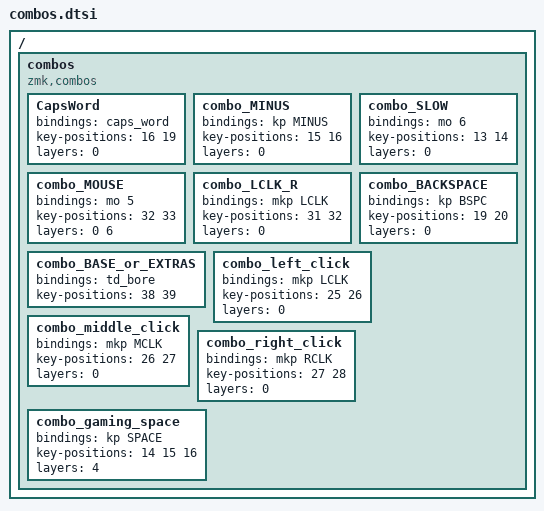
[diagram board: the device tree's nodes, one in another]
/ {
    combos {
        compatible = "zmk,combos";

        CapsWord {
            bindings = <&caps_word>;
            key-positions = <16 19>;
            layers = <0>;
        };

        combo_MINUS {
            bindings = <&kp MINUS>;
            key-positions = <15 16>;
            layers = <0>;
        };

        combo_SLOW {
            bindings = <&mo 6>;
            key-positions = <13 14>;
            layers = <0>;
        };

        combo_MOUSE {
            bindings = <&mo 5>;
            key-positions = <32 33>;
            layers = <0 6>;
        };

        combo_LCLK_R {
            bindings = <&mkp LCLK>;
            key-positions = <31 32>;
            layers = <0>;
        };

        combo_BACKSPACE {
            bindings = <&kp BSPC>;
            key-positions = <19 20>;
            layers = <0>;
        };

        combo_BASE_or_EXTRAS {
            bindings = <&td_bore>;
            key-positions = <38 39>;
        };

        combo_left_click {
            bindings = <&mkp LCLK>;
            key-positions = <25 26>;
            layers = <0>;
        };

        combo_middle_click {
            bindings = <&mkp MCLK>;
            key-positions = <26 27>;
            layers = <0>;
        };

        combo_right_click {
            bindings = <&mkp RCLK>;
            key-positions = <27 28>;
            layers = <0>;
        };

        combo_gaming_space {
            bindings = <&kp SPACE>;
            key-positions = <14 15 16>;
            layers = <4>;
        };
    };
};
